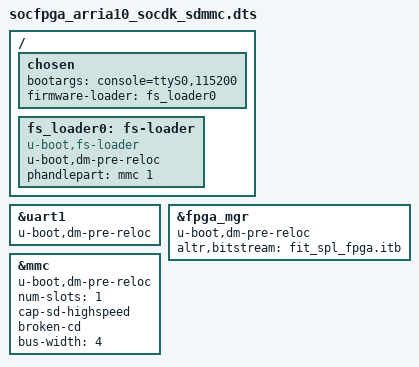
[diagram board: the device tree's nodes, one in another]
/*
 * Copyright (C) 2015-2017 Altera Corporation. All rights reserved.
 *
 * This program is free software; you can redistribute it and/or modify
 * it under the terms and conditions of the GNU General Public License,
 * version 2, as published by the Free Software Foundation.
 *
 * This program is distributed in the hope it will be useful, but WITHOUT
 * ANY WARRANTY; without even the implied warranty of MERCHANTABILITY or
 * FITNESS FOR A PARTICULAR PURPOSE.  See the GNU General Public License for
 * more details.
 *
 * You should have received a copy of the GNU General Public License along with
 * this program.  If not, see <http://www.gnu.org/licenses/>.
 */

/dts-v1/;
#include "socfpga_arria10_socdk_sdmmc_handoff.dtsi"

/ {
	chosen {
		bootargs = "console=ttyS0,115200";
	};
};

&uart1 {
	u-boot,dm-pre-reloc;
	status = "okay";
};

/ {
	chosen {
		firmware-loader = <&fs_loader0>;
	};

	fs_loader0: fs-loader {
		u-boot,dm-pre-reloc;
		compatible = "u-boot,fs-loader";
		phandlepart = <&mmc 1>;
	};
};

&fpga_mgr {
	u-boot,dm-pre-reloc;
	altr,bitstream = "fit_spl_fpga.itb";
};

&mmc {
	u-boot,dm-pre-reloc;
	status = "okay";
	num-slots = <1>;
	cap-sd-highspeed;
	broken-cd;
	bus-width = <4>;
};
